# MSP432P401R register map
Vendor: Texas Instruments; File version: 3.220
Registers are 32-bit, read-write, reset 0x0 unless marked. A register's access mark holds for its fields unless they carry their own. Offsets are from the block's base; [hi:lo] are bit positions; {n}, {i} and the like mark numbered series; 'fields as' and 'values as' point back to an identical list.

## CAPTIO0
Base 0x40005400
Same registers: CAPTIO1 0x40005800
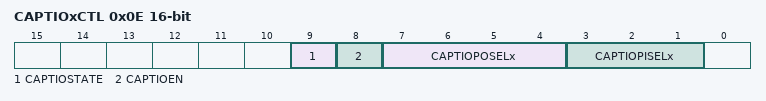
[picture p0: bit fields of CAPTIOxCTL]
0x0E CAPTIOxCTL 16-bit — Capacitive Touch IO x Control Register
  [9] CAPTIOSTATE ro — Capacitive Touch IO state
    on read: 0=Curent state 0 or Capacitive Touch IO is disabled; 1=Current state 1
  [8] CAPTIOEN — Capacitive Touch IO enable
    0=All Capacitive Touch IOs are disabled. Signal towards timers is 0.; 1=Selected Capacitive Touch IO is enabled
  [7:4] CAPTIOPOSELx — Capacitive Touch IO port select
    0=Px = PJ; {v}=Px = P{v} (v=1..15)
  [3:1] CAPTIOPISELx — Capacitive Touch IO pin select
    0=Px.0; 1=Px.1; 2=Px.2; 3=Px.3; 4=Px.4; 5=Px.5; 6=Px.6; 7=Px.7

## TIMER32
Base 0x4000C000
0x00 T32LOAD1 — Timer 1 Load Register
  [31:0] LOAD — The value from which the Timer 1 counter decrements
0x04 T32VALUE1 ro reset 0xFFFFFFFF — Timer 1 Current Value Register
  [31:0] VALUE — Current value
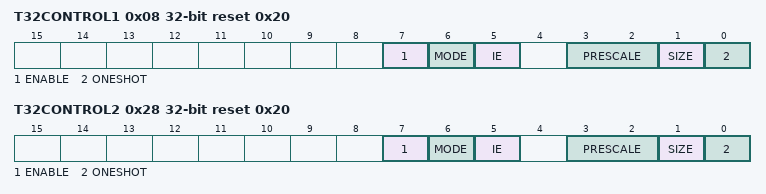
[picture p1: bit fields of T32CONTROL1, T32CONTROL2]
0x08 T32CONTROL1 reset 0x20 — Timer 1 Timer Control Register
  [7] ENABLE — Enable bit
    0=Timer disabled; 1=Timer enabled
  [6] MODE — Mode bit
    0=Timer is in free-running mode; 1=Timer is in periodic mode
  [5] IE — Interrupt enable bit
    0=Timer interrupt disabled; 1=Timer interrupt enabled
  [3:2] PRESCALE — Prescale bits
    0=0 stages of prescale, clock is divided by 1; 1=4 stages of prescale, clock is divided by 16; 2=8 stages of prescale, clock is divided by 256
  [1] SIZE — Selects 16 or 32 bit counter operation
    0=16-bit counter; 1=32-bit counter
  [0] ONESHOT — Selects one-shot or wrapping counter mode
    0=wrapping mode; 1=one-shot mode
0x0C T32INTCLR1 wo reset not defined — Timer 1 Interrupt Clear Register
  [31:0] INTCLR — Write clears interrupt output
0x10 T32RIS1 ro — Timer 1 Raw Interrupt Status Register
  [0] RAW_IFG — Raw interrupt status
0x14 T32MIS1 ro — Timer 1 Interrupt Status Register
  [0] IFG — Enabled interrupt status
0x18 T32BGLOAD1 — Timer 1 Background Load Register
  [31:0] BGLOAD — Value from which the counter decrements
0x20 T32LOAD2 — Timer 2 Load Register
  [31:0] LOAD — The value from which the Timer 2 counter decrements
0x24 T32VALUE2 ro reset 0xFFFFFFFF — Timer 2 Current Value Register
  [31:0] VALUE — Current value of the decrementing counter
0x28 T32CONTROL2 reset 0x20 — Timer 2 Timer Control Register
  fields as T32CONTROL1
0x2C T32INTCLR2 wo reset not defined — Timer 2 Interrupt Clear Register
  [31:0] INTCLR — Write clears the interrupt output
0x30 T32RIS2 ro — Timer 2 Raw Interrupt Status Register
  [0] RAW_IFG — Raw interrupt status
0x34 T32MIS2 ro — Timer 2 Interrupt Status Register
  [0] IFG — Enabled interrupt status
0x38 T32BGLOAD2 — Timer 2 Background Load Register
  [31:0] BGLOAD — Value from which the counter decrements

## PCM
Base 0x40010000
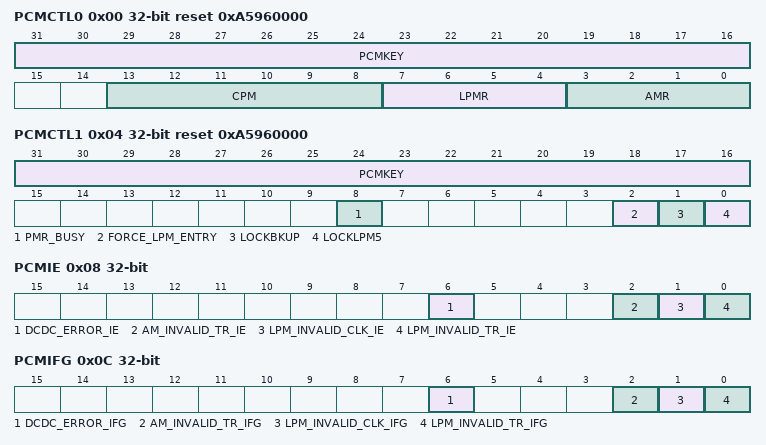
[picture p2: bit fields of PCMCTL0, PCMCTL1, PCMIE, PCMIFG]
0x00 PCMCTL0 reset 0xA5960000 — Control 0 Register
  [31:16] PCMKEY
  [13:8] CPM ro — Current Power Mode
    on read: 0=LDO based Active Mode at Core voltage setting 0; 1=LDO based Active Mode at Core voltage setting 1; 4=DC-DC based Active Mode at Core voltage setting 0; 5=DC-DC based Active Mode at Core voltage setting 1; 8=Low-Frequency Active Mode at Core voltage setting 0; 9=Low-Frequency Active Mode at Core voltage setting 1; 16=LDO based LPM0 at Core voltage setting 0; 17=LDO based LPM0 at Core voltage setting 1; 20=DC-DC based LPM0 at Core voltage setting 0; 21=DC-DC based LPM0 at Core voltage setting 1; 24=Low-Frequency LPM0 at Core voltage setting 0; 25=Low-Frequency LPM0 at Core voltage setting 1; 32=LPM3
  [7:4] LPMR — Low Power Mode Request
    0=LPM3. Core voltage setting is similar to the mode from which LPM3 is entered.; 10=LPM3.5. Core voltage setting 0.; 12=LPM4.5
  [3:0] AMR — Active Mode Request
    0=LDO based Active Mode at Core voltage setting 0; 1=LDO based Active Mode at Core voltage setting 1; 4=DC-DC based Active Mode at Core voltage setting 0; 5=DC-DC based Active Mode at Core voltage setting 1; 8=Low-Frequency Active Mode at Core voltage setting 0; 9=Low-Frequency Active Mode at Core voltage setting 1
0x04 PCMCTL1 reset 0xA5960000 — Control 1 Register
  [31:16] PCMKEY
  [8] PMR_BUSY — Power mode request busy flag
  [2] FORCE_LPM_ENTRY
    0=PCM aborts LPM3/LPMx.5 transition if the active clock configuration does not meet the LPM3/LPMx.5 entry criteria. PCM generates the LPM_INVALID_CLK flag on abort to LPM3/LPMx.5 entry.; 1=PCM enters LPM3/LPMx.5 after shuting off the clocks forcefully. Application needs to ensure RTC and WDT are clocked using BCLK tree to keep these modules alive in LPM3/LPM3.5. In LPM4.5 all clocks are forcefully shutoff and the core voltage is turned off.
  [1] LOCKBKUP — Lock Backup
    0=Backup domain configuration defaults to reset condition; 1=Backup domain configuration remains locked during LPM3.5 entry and exit
  [0] LOCKLPM5
    0=LPMx.5 configuration defaults to reset condition; 1=LPMx.5 configuration remains locked during LPMx.5 entry and exit
0x08 PCMIE — Interrupt Enable Register
  [all] fields
    0=Disabled; 1=Enabled
  [6] DCDC_ERROR_IE — DC-DC error interrupt enable
  [2] AM_INVALID_TR_IE — Active mode invalid transition interrupt enable
  [1] LPM_INVALID_CLK_IE — LPM invalid clock interrupt enable
  [0] LPM_INVALID_TR_IE — LPM invalid transition interrupt enable
0x0C PCMIFG ro — Interrupt Flag Register
  [6] DCDC_ERROR_IFG — DC-DC error flag
  [2] AM_INVALID_TR_IFG — Active mode invalid transition flag
  [1] LPM_INVALID_CLK_IFG — LPM invalid clock flag
  [0] LPM_INVALID_TR_IFG — LPM invalid transition flag
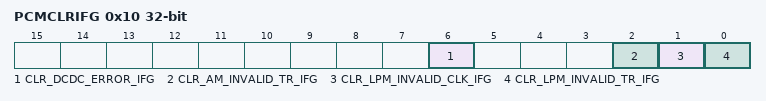
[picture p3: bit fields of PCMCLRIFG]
0x10 PCMCLRIFG wo — Clear Interrupt Flag Register
  [6] CLR_DCDC_ERROR_IFG — Clear DC-DC error flag
  [2] CLR_AM_INVALID_TR_IFG — Clear active mode invalid transition flag
  [1] CLR_LPM_INVALID_CLK_IFG — Clear LPM invalid clock flag
  [0] CLR_LPM_INVALID_TR_IFG — Clear LPM invalid transition flag
